# BAT32G157 register map
Vendor: Cmsemicon; Series: BAT32G157; File version: 1.0
CPU: CM0+ r0p1, little endian, no MPU, no FPU, VTOR, 2 interrupt priority bits
Registers are 8-bit, read-write, reset 0x0 unless marked. A register's access mark holds for its fields unless they carry their own. Offsets are from the block's base; [hi:lo] are bit positions; {n}, {i} and the like mark numbered series.

## SSI — Serial Sound Interface
Base 0x40090000
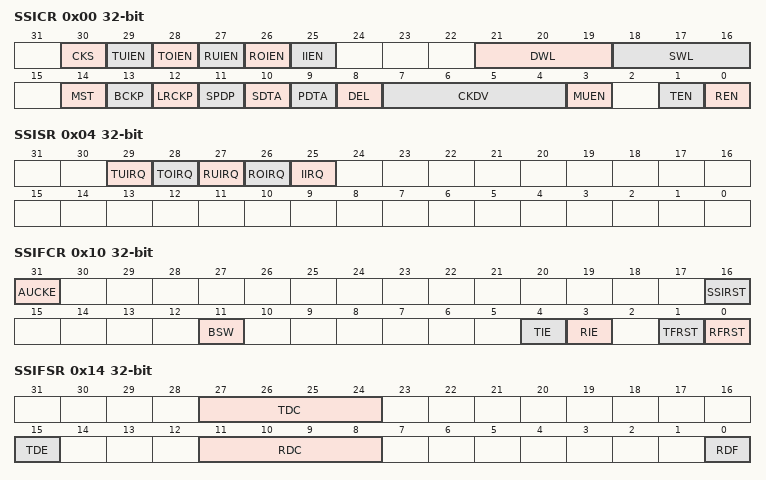
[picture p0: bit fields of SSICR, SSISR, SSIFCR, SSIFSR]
0x00 SSICR 32-bit — Control Register
  [30] CKS — Select an Audio Clock for Master Mode Communication
  [29] TUIEN — Transmit Underflow Interrupt Output Enable
  [28] TOIEN — Transmit Overflow Interrupt Output Enable
  [27] RUIEN — Receive Underflow Interrupt Output Enable
  [26] ROIEN — Receive Overflow Interrupt Output Enable
  [25] IIEN — Idle Mode Interrupt Output Enable
  [21:19] DWL — Select Data Word Length
  [18:16] SWL — Select System Word Length
  [14] MST — Master Enable
  [13] BCKP — Select Bit Clock Polarity
  [12] LRCKP — Select the Initial Value and Polarity of LR Clock/Frame Synchronization Signal
  [11] SPDP — Select Serial Padding Polarity
  [10] SDTA — Select Serial Data Alignment
  [9] PDTA — Select Placement Data Alignment
  [8] DEL — Select Serial Data Delay
  [7:4] CKDV — Select Bit Clock Division Ratio
  [3] MUEN — Mute Enable
  [1] TEN — Transmission Enable
  [0] REN — Reception Enable
0x04 SSISR 32-bit — Status Register
  [29] TUIRQ — Transmit Underflow Error Status Flag
  [28] TOIRQ — Transmit Overflow Error Status Flag
  [27] RUIRQ — Receive Underflow Error Status Flag
  [26] ROIRQ — Receive Overflow Error Status Flag
  [25] IIRQ — Idle Mode Status Flag
0x10 SSIFCR 32-bit (reset mask 0x8001080F) — FIFO Control Register
  [31] AUCKE — AUDIO_MCK Enable in Master Mode Communication
  [16] SSIRST — Software Reset
  [11] BSW — Byte Swap Enable
  [4] TIE — Transmit Data Empty Interrupt Output Enable
  [3] RIE — Receive Data Full Interrupt Output Enable
  [1] TFRST — Transmit FIFO Data Register Reset
  [0] RFRST — Receive FIFO Data Register Reset
0x14 SSIFSR 32-bit (reset mask 0xF010F01) — FIFO Status Register
  [27:24] TDC — Number of Transmit FIFO Data Indication Flag
  [15] TDE — Transmit Data Empty Flag
  [11:8] RDC — Number of Receive FIFO Data Indication Flag
  [0] RDF — Receive Data Full Flag
0x18 SSIFTDR 32-bit — Transmit FIFO Data Register
0x1C SSIFRDR 32-bit — Receive FIFO Data Register
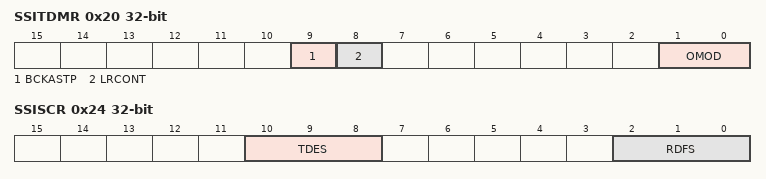
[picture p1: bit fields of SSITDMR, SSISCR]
0x20 SSITDMR 32-bit — TDM Mode Register
  [9] BCKASTP — Enable Stopping BCK Output When SSIE is in Idle Status
  [8] LRCONT ro — Enable LRCK/FS Continuation
  [1:0] OMOD — Audio Format Select
0x24 SSISCR 32-bit — Status Control Register
  [10:8] TDES — TDE Setting Condition Select
  [2:0] RDFS — RDF Setting Condition Select

## LCDB — LCD Bus Interface
Base 0x40045400
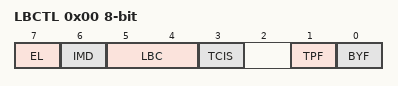
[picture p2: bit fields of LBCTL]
0x00 LBCTL — LCD Bus Interface mode register
  [7] EL — Control the level of signal "E" in mod68 mode
  [6] IMD — Mode of external bus interface access selection
  [5:4] LBC — Internal clock (SPCLK) selection
  [3] TCIS — INTLCDB (DMA trigger) generation control bit
  [1] TPF — Flag of transfer in progress on external bus interface
  [0] BYF — Data register busy flag
0x01 LBCYC — LCB Bus Interface cycle control register
0x02 LBWST — LCB Bus Interface wait control register
0x10 LBDATA 16-bit — LCD Bus Interface data register
0x10 LBDATAL (alternate view of LBDATA) — SPI data register
0x12 LBDATAR 16-bit — LCD Bus Interface read data register
0x12 LBDATARL (alternate view of LBDATAR) — LCD Bus Interface read data register

## DBG — DBG Controller
Base 0x4001B000
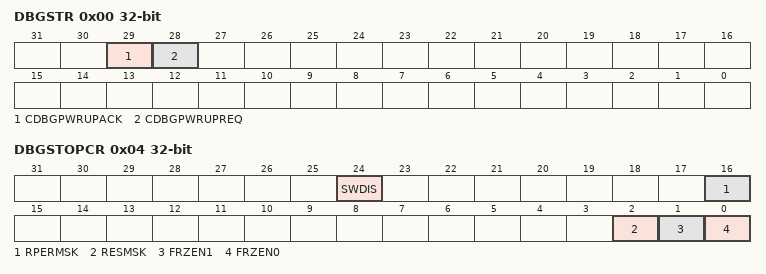
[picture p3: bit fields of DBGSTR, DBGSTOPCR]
0x00 DBGSTR 32-bit ro — Debug status register
  [29] CDBGPWRUPACK — DBG Power Up Acknowledgement
  [28] CDBGPWRUPREQ — DBG Power Up Request
0x04 DBGSTOPCR 32-bit — Debug Stop Control register
  [24] SWDIS — SWD Disable
  [16] RPERMSK — Mask RAM parity error in debug mode
  [2] RESMSK — Mask internal reset in debug mode
  [1] FRZEN1 — Stop Communation family macros when cpu halted
  [0] FRZEN0 — Stop Timer family macros when cpu halted

## BGR — Temperature Sensor calibration data
Base 0x08500C60
0x00 VBG85 16-bit ro — The A/D conversion value of VBGR at 85 degrees and 3.0V reference voltage
0x04 VBG25 16-bit ro — The A/D conversion value of VBGR at 25 degrees and 3.0V reference voltage

## TSN — Temperature Sensor calibration data
Base 0x08500C68
0x00 TSN85 16-bit ro — The A/D conversion value of Temperature Sensor at 85 degrees and 3.0V reference voltage
0x04 TSN25 16-bit ro — The A/D conversion value of Temperature Sensor at 25 degrees and 3.0V reference voltage

## UID — 128-bit Unique ID
Base 0x0850084C
{0x0+4i} UID{i} (i=0..3) 32-bit ro — UID word {i}
